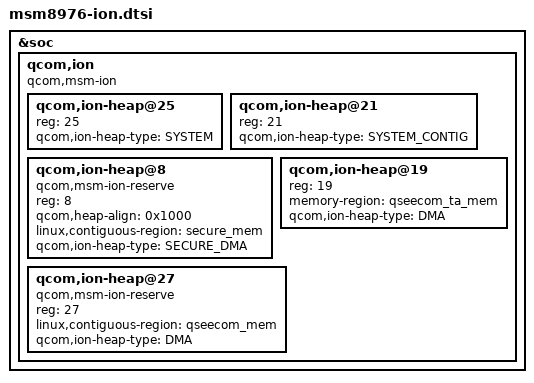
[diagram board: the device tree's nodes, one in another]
// SPDX-License-Identifier: GPL-2.0
// Copyright (c) 2014, The Linux Foundation. All rights reserved.
// Copyright (c) 2023, Benarji Anand <benarji385@gmail.com>

&soc {
	qcom,ion {
		compatible = "qcom,msm-ion";
		#address-cells = <1>;
		#size-cells = <0>;

		qcom,ion-heap@25 {
			reg = <25>;
			qcom,ion-heap-type = "SYSTEM";
		};

		qcom,ion-heap@21 {
			reg = <21>;
			qcom,ion-heap-type = "SYSTEM_CONTIG";
		};

		qcom,ion-heap@8 { /* CP_MM HEAP */
			compatible = "qcom,msm-ion-reserve";
			reg = <8>;
			qcom,heap-align = <0x1000>;
			linux,contiguous-region = <&secure_mem>;
			qcom,ion-heap-type = "SECURE_DMA";
		};

		qcom,ion-heap@19 { /* QSEECOM TA HEAP */
			reg = <19>;
			memory-region = <&qseecom_ta_mem>;
			qcom,ion-heap-type = "DMA";
		};

		qcom,ion-heap@27 { /* QSEECOM HEAP */
			compatible = "qcom,msm-ion-reserve";
			reg = <27>;
			linux,contiguous-region = <&qseecom_mem>;
			qcom,ion-heap-type = "DMA";
		};
	};
};
